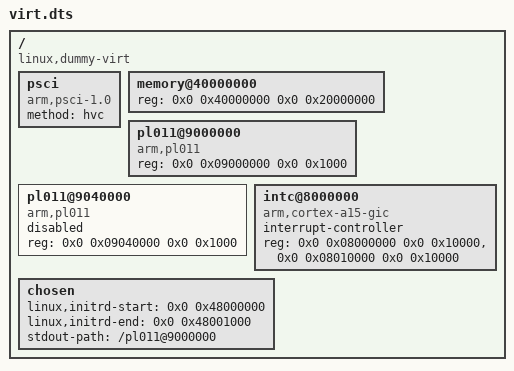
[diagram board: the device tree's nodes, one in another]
// SPDX-License-Identifier: GPL-3.0-or-later
// Copyright (C) 2026 Sergey Subbotin <ssubbotin@gmail.com>
/dts-v1/;
/memreserve/ 0x48000000 0x1000;
/ {
	#address-cells = <2>;
	#size-cells = <2>;
	compatible = "linux,dummy-virt";

	psci {
		compatible = "arm,psci-1.0", "arm,psci-0.2", "arm,psci";
		method = "hvc";
	};

	memory@40000000 {
		device_type = "memory";
		reg = <0x0 0x40000000 0x0 0x20000000>;
	};

	pl011@9000000 {
		compatible = "arm,pl011", "arm,primecell";
		reg = <0x0 0x09000000 0x0 0x1000>;
	};

	pl011@9040000 {
		compatible = "arm,pl011", "arm,primecell";
		reg = <0x0 0x09040000 0x0 0x1000>;
		status = "disabled";
	};

	intc@8000000 {
		compatible = "arm,cortex-a15-gic";
		#interrupt-cells = <3>;
		interrupt-controller;
		reg = <0x0 0x08000000 0x0 0x10000>, <0x0 0x08010000 0x0 0x10000>;
	};

	chosen {
		linux,initrd-start = <0x0 0x48000000>;
		linux,initrd-end = <0x0 0x48001000>;
		stdout-path = "/pl011@9000000";
	};
};
